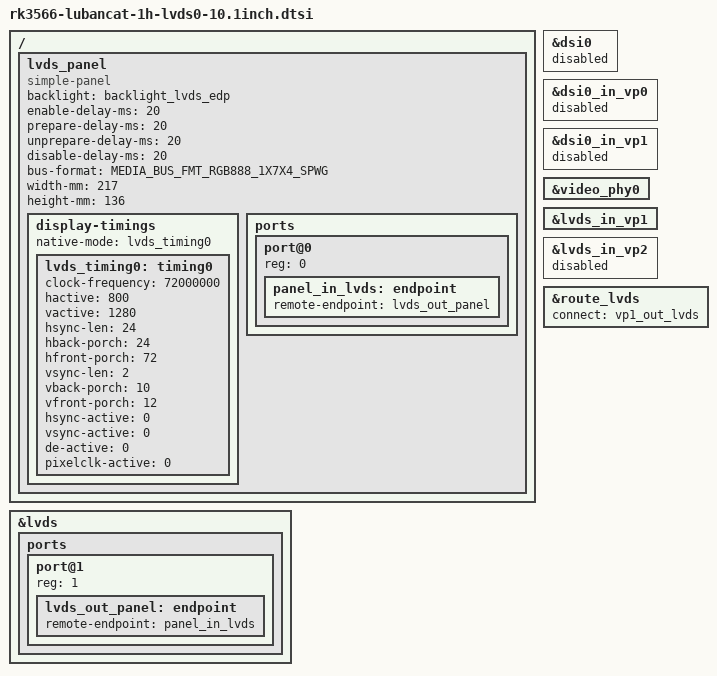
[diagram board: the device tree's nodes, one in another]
// SPDX-License-Identifier: (GPL-2.0+ OR MIT)
#include <dt-bindings/display/media-bus-format.h>

/ {
	lvds_panel {
		compatible = "simple-panel";
		backlight = <&backlight_lvds_edp>;

		enable-delay-ms = <20>;
		prepare-delay-ms = <20>;
		unprepare-delay-ms = <20>;
		disable-delay-ms = <20>;

		bus-format = <MEDIA_BUS_FMT_RGB888_1X7X4_SPWG>;

		width-mm = <217>;
		height-mm = <136>;

		display-timings {
			native-mode = <&lvds_timing0>;
			/* HKBY101R28HM25-L LVDS panel */
			lvds_timing0: timing0 {
				clock-frequency = <72000000>;
				hactive = <800>;
				vactive = <1280>;
				hsync-len = <24>;
				hback-porch = <24>;
				hfront-porch = <72>;
				vsync-len = <2>;
				vback-porch = <10>;
				vfront-porch = <12>;
				hsync-active = <0>;
				vsync-active = <0>;
				de-active = <0>;
				pixelclk-active = <0>;
			};
		};

		ports {
			#address-cells = <1>;
			#size-cells = <0>;
			port@0 {
				reg = <0>;
//				dual-lvds-even-pixels;
				panel_in_lvds: endpoint {
					remote-endpoint = <&lvds_out_panel>;
				};
			};
		};
	};
};

&dsi0 {
	status = "disabled";
};

&dsi0_in_vp0 {
	status = "disabled";
};

&dsi0_in_vp1 {
	status = "disabled";
};

&video_phy0 {
	status = "okay";
};

&lvds_in_vp1 {
	status = "okay";
};

&lvds_in_vp2 {
	status = "disabled";
};

&route_lvds {
	status = "okay";
	connect = <&vp1_out_lvds>;
};

&lvds {
	status = "okay";
	ports {
		port@1 {
			reg = <1>;
			lvds_out_panel: endpoint {
				remote-endpoint = <&panel_in_lvds>;
			};
		};
	};
};
